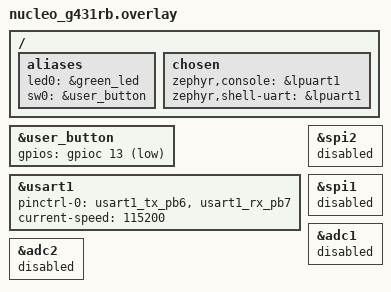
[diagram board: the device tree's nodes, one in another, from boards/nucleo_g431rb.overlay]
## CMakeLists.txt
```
# SPDX-License-Identifier: Apache-2.0

cmake_minimum_required(VERSION 3.20.0)

if(NOT BUILD_TESTING)
    find_package(Zephyr REQUIRED HINTS $ENV{ZEPHYR_BASE})
endif()

project(CubeMot)

# ── msghub location (parameterized; default matches the workspace layout) ────
# Override with -DMSGHUB_DIR=<path> when msghub lives elsewhere (e.g. a west
# module checkout, a vendored copy, or a CI workspace).
set(MSGHUB_DIR "${CMAKE_SOURCE_DIR}/../msghub" CACHE PATH "Path to the msghub repository")
if(NOT EXISTS "${MSGHUB_DIR}/include/msghub/msghub.h")
    message(FATAL_ERROR "msghub not found at ${MSGHUB_DIR}; pass -DMSGHUB_DIR=<path> to point at the msghub repository")
endif()

if(BUILD_TESTING)
    enable_testing()
    add_subdirectory(tests)
else()
    add_subdirectory(src)
endif()
```

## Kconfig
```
mainmenu "CubeMot Application"

source "Kconfig.zephyr"

# Core infrastructure — msghub capacity configuration (consumer-side glue)
menu "Message Hub Configuration"

config MSGHUB_MAX_TOPICS
	int "Maximum number of topics"
	default 8
	range 4 32
	help
	  Maximum number of unique topics that can be registered.

config MSGHUB_MAX_INSTANCES
	int "Maximum instances per topic"
	default 4
	range 1 16
	help
	  Maximum number of publisher instances per topic.

config MSGHUB_MAX_SUBSCRIBERS
	int "Maximum number of subscribers"
	default 16
	range 8 64
	help
	  Maximum total number of subscriber handles.

config MSGHUB_MAX_MSG_SIZE
	int "Maximum message size (bytes)"
	default 128
	range 16 1024
	help
	  Size of the per-topic last-value data buffer.

endmenu

# CubeMot application modules (rsource = relative to this Kconfig file)
rsource "src/modules/blink/Kconfig"
rsource "src/modules/button_detector/Kconfig"
rsource "src/modules/led_controller/Kconfig"
rsource "src/modules/motor_ctrl/Kconfig"

rsource "src/comm/serial_cmd/Kconfig"
```

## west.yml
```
manifest:
  defaults:
    remote: upstream

  remotes:
    - name: upstream
      url-base: https://github.com/zephyrproject-rtos

  group-filter: [-babblesim, -optional, -testing]

  projects:
    - name: zephyr
      revision: v4.4.1
      west-commands: scripts/west-commands.yml
    - name: cmsis
      revision: 512cc7e895e8491696b61f7ba8066b4a182569b8
      path: modules/hal/cmsis
      groups:
        - hal
    - name: cmsis_6
      repo-path: CMSIS_6
      revision: 30a859f44ef8ab4dc8f84b03ed586fd16ccf9d74
      path: modules/hal/cmsis_6
      groups:
        - hal
    - name: hal_stm32
      revision: fc11896dd39cfca37bf9b4aeaaa2df8861b81875
      path: modules/hal/stm32
      groups:
        - hal

  self:
    path: cubemot-esc
```

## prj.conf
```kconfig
CONFIG_GPIO=y
CONFIG_LED=y
CONFIG_LED_GPIO=y
CONFIG_INPUT=y
CONFIG_INPUT_GPIO_KEYS=y

CONFIG_PRINTK=y
CONFIG_SHELL=y
CONFIG_SHELL_BACKEND_SERIAL=y
CONFIG_SHELL_BACKEND_SERIAL_INTERRUPT_DRIVEN=y
CONFIG_SHELL_STACK_SIZE=4096
CONFIG_SHELL_THREAD_PRIORITY=14
CONFIG_LOG_BACKEND_UART=n
CONFIG_THREAD_MONITOR=y

# CubeMot modules
CONFIG_NEWLIB_LIBC=n
CONFIG_PICOLIBC=y
CONFIG_FPU=y

# Module enable flags
CONFIG_MODULE_LED_CONTROLLER_ENABLE=n
CONFIG_MODULE_BUTTON_DETECTOR_ENABLE=n
CONFIG_MODULE_BLINK_ENABLE=n
CONFIG_MODULE_MOTOR_CTRL_ENABLE=y

CONFIG_MODULE_SERIAL_CMD_ENABLE=y


# Thread stack sizes
CONFIG_MAIN_STACK_SIZE=1024

CONFIG_MOTOR_CTRL_STACK_SIZE=1536

# ADC for FOC
CONFIG_ADC=y
CONFIG_LOG=y
CONFIG_LOG_BUFFER_SIZE=256
CONFIG_LOG_DEFAULT_LEVEL=0
CONFIG_LOG_OVERRIDE_LEVEL=0
CONFIG_LOG_BACKEND_UART=n
CONFIG_LOG_MODE_DEFERRED=n

# UART interrupt-driven API (for serial_cmd RX)
CONFIG_SERIAL=y
CONFIG_UART_INTERRUPT_DRIVEN=y

# STM32 HAL LL drivers (used directly by FOC code)
CONFIG_CLOCK_CONTROL=y
CONFIG_PINCTRL=y
```

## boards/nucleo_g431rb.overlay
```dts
/ {
	aliases {
		led0 = &green_led;
		sw0 = &user_button;
	};

	/*
	 * Console on LPUART1 (PA2/PA3) — ST-Link V3 VCP bridges LPUART1.
	 * Shell and log output accessible via /dev/ttyACM0.
	 */
	chosen {
		zephyr,console = &lpuart1;
		zephyr,shell-uart = &lpuart1;
	};
};

&user_button {
	/*
	 * PC13 on Nucleo-G431RB is active-low (pull-up, GND when pressed).
	 * The base board DTS incorrectly uses GPIO_ACTIVE_HIGH.
	 * Override with correct polarity and enable pull-up.
	 */
	gpios = <&gpioc 13 (GPIO_PULL_UP | GPIO_ACTIVE_LOW)>;
};

/*
 * USART1 on PB6(TX)/PB7(RX) — NOT bridged by ST-Link V3 VCP.
 * Used for VCU↔ESC serial link (serial_cmd module).
 * Remapped from default PC4/PC5 (PC5 conflicts with ADC2_IN11 Vbus).
 */
&usart1 {
	pinctrl-0 = <&usart1_tx_pb6 &usart1_rx_pb7>;
	pinctrl-names = "default";
	current-speed = <115200>;
	status = "okay";
};

/*
 * Disable SPI2: PB13/PB14/PB15 needed by TIM1_CH1N/CH2N/CH3N
 * for FOC complementary PWM outputs.
 */
&spi2 {
	status = "disabled";
};

/*
 * Disable SPI1: PA7 (MOSI) needed by ADC2_IN4 for Phase W current sensing.
 * PA5 (SCK) and PA6 (MISO) kept free for future use.
 */
&spi1 {
	status = "disabled";
};

/*
 * ADC1/ADC2 kept DISABLED — Zephyr ADC driver must NOT initialize them.
 * Our foc_adc_init() handles all ADC configuration directly via LL registers.
 * The ADC12 bus clock is enabled manually in foc_adc_init() via
 * LL_AHB2_GRP1_EnableClock(LL_AHB2_GRP1_PERIPH_ADC12).
 */
&adc1 {
	status = "disabled";
};

&adc2 {
	status = "disabled";
};
```

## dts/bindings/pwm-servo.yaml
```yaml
description: PWM-driven servo motor (50Hz, 500-2500us pulse width)

compatible: "pwm-servo"

include: base.yaml

properties:
  pwms:
    required: true
    type: phandle-array
    description: |
      PWM channels for servo control.
      Period should be 20ms (50Hz). Pulse width 500-2500us maps to -90/+90 deg.

  pwm-names:
    required: true
    type: string-array
    description: Names for each PWM channel.
```

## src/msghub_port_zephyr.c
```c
// CubeMot ESC — msghub Zephyr adapter (framework glue, lives in the consumer repo).
//
// The msghub repo is framework-agnostic: its core only calls the msghub_port_*
// abstract interface and ships weak no-op defaults. This file provides the
// strong Zephyr implementations, overriding the weak ones at link time.

#include "msghub/msghub_port.h"

#include <zephyr/kernel.h>

static struct k_mutex s_msghub_mgr_mutex;

void msghub_port_init(void)
{
    k_mutex_init(&s_msghub_mgr_mutex);
}

void msghub_port_deinit(void)
{
    // Zephyr k_mutex does not need explicit deinit
}

void msghub_port_mgr_lock(void)
{
    k_mutex_lock(&s_msghub_mgr_mutex, K_FOREVER);
}

void msghub_port_mgr_unlock(void)
{
    k_mutex_unlock(&s_msghub_mgr_mutex);
}

void msghub_port_enter_critical(void)
{
    k_sched_lock();
}

void msghub_port_exit_critical(void)
{
    k_sched_unlock();
}

uint32_t msghub_port_enter_critical_isr(void)
{
    return (uint32_t)irq_lock();
}

void msghub_port_exit_critical_isr(uint32_t key)
{
    irq_unlock((int)key);
}

void msghub_port_sleep_ms(uint32_t ms)
{
    k_sleep(K_MSEC(ms));
}
```
